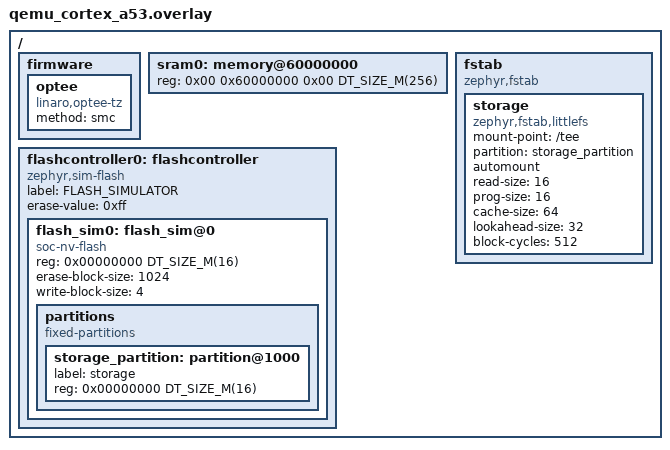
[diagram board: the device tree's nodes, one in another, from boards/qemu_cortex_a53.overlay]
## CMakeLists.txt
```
# SPDX-License-Identifier: GPL-v2
#
# Copyright (c) 2023 EPAM Systems
# Author: Dmytro Semenets <dmytro_semenets@epam.com>

cmake_minimum_required(VERSION 3.20.0)
find_package(Zephyr REQUIRED HINTS $ENV{ZEPHYR_BASE})
include($ENV{ZEPHYR_BASE}/cmake/app/boilerplate.cmake NO_POLICY_SCOPE)
project(zephyr-optee-test)
find_package(Python REQUIRED)

set(EMBED_8100FILE_DIR ${CMAKE_CURRENT_BINARY_DIR}/zephyr/include/generated)
macro(EMBED_8100FILE prefix infile)
	add_custom_command(
		OUTPUT  ${EMBED_8100FILE_DIR}/regression_8100_${prefix}.h
		COMMAND ${Python_EXECUTABLE} ${CMAKE_CURRENT_SOURCE_DIR}/scripts/file_to_c.py --inf ${infile}
			--out ${EMBED_8100FILE_DIR}/regression_8100_${prefix}.h
			--name regression_8100_${prefix}
		DEPENDS ${CMAKE_CURRENT_SOURCE_DIR}/scripts/file_to_c.py ${infile}
	)

	set_property(SOURCE src/regression_8100.c APPEND PROPERTY OBJECT_DEPENDS
		     ${EMBED_8100FILE_DIR}/regression_8100_${prefix}.h)
endmacro(EMBED_8100FILE)

EMBED_8100FILE(ca_crt ${CMAKE_CURRENT_SOURCE_DIR}/cert/ca.crt)
EMBED_8100FILE(mid_crt ${CMAKE_CURRENT_SOURCE_DIR}/cert/mid.crt)
EMBED_8100FILE(my_crt ${CMAKE_CURRENT_SOURCE_DIR}/cert/my.crt)
EMBED_8100FILE(my_csr ${CMAKE_CURRENT_SOURCE_DIR}/cert/my.csr)

zephyr_library_sources(adbg/src/adbg_expect.c)
zephyr_library_sources(adbg/src/adbg_log.c)
zephyr_library_sources(adbg/src/security_utils_hex.c)
zephyr_include_directories(adbg/include)

zephyr_library_include_directories(include)
zephyr_library_sources(src/optee_test.c)
zephyr_library_sources(src/xtest_helpers.c)

zephyr_library_sources(src/regression_1000.c)
zephyr_library_sources(src/pkcs11_1000.c)
zephyr_library_sources(src/regression_4000.c)
zephyr_library_sources(src/regression_4100.c)
zephyr_library_sources(src/regression_6000.c)
zephyr_library_sources(src/regression_8000.c)
zephyr_library_sources(src/regression_8100.c)
# ######################################################################################################################
# External libs
# ######################################################################################################################

zephyr_library_include_directories(${ZEPHYR_OPTEELIB_MODULE_DIR}/public)

# ######################################################################################################################
# Prebuilt TAs
# ######################################################################################################################

if(TA_DEPLOY_DIR)
    message(WARNING "Setting up TAs")
    set(TA_BIN_DIRECTORY ta_bin)
    set(GENERATED_DIRECTORY ta_table)
    add_custom_command(
        OUTPUT
            ${GENERATED_DIRECTORY}/ta_table.c
            ${GENERATED_DIRECTORY}/ta_table.S
        COMMAND ${CMAKE_CURRENT_SOURCE_DIR}/scripts/prepare_ta.sh
                -s ${CMAKE_CURRENT_SOURCE_DIR}
                -f ${TA_DEPLOY_DIR}
                -b ${TA_BIN_DIRECTORY}
                -g ${GENERATED_DIRECTORY}
    )
    include_directories(app PRIVATE ${CMAKE_CURRENT_BINARY_DIR}/${TA_BIN_DIRECTORY})
    zephyr_library_sources(${GENERATED_DIRECTORY}/ta_table.c)
    zephyr_library_sources(${GENERATED_DIRECTORY}/ta_table.S)

endif()
```

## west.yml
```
# SPDX-License-Identifier: Apache-2.0

manifest:
  self:
    path: zephyr-optee-test

  remotes:
    - name: xentroops
      url-base: https://github.com/xen-troops

    - name: zephyr
      url-base: https://github.com/zephyrproject-rtos

  projects:
    - name: zephyr
      remote: xentroops
      revision: zephyr-v4.4.0-xt
      west-commands: scripts/west-commands.yml

    - name: zephyr-optee-client
      remote: xentroops
      revision: master

    - name: littlefs
      remote: zephyr
      path: modules/fs/littlefs
      groups:
        - fs
      revision: ca583fd297ceb48bced3c2548600dc615d67af24
```

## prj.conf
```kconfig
CONFIG_ZTEST=y
CONFIG_OPTEE_CLIENT=y
CONFIG_OPTEE_LIBTEEC=y
CONFIG_OPTEE_LIBCKTEEC=y
CONFIG_HEAP_MEM_POOL_SIZE=8388608
CONFIG_KERNEL_VM_SIZE=0x4000000
CONFIG_TEE=y
CONFIG_OPTEE=y
CONFIG_COMMON_LIBC_MALLOC_ARENA_SIZE=4096
CONFIG_ZTEST_STACK_SIZE=65536

CONFIG_POSIX_TIMERS=y
CONFIG_OPTEE_TEE_SUPPLICANT=y
CONFIG_FILE_SYSTEM=y
CONFIG_FILE_SYSTEM_LITTLEFS=y
CONFIG_POSIX_FILE_SYSTEM=y
CONFIG_POSIX_API=y
CONFIG_DISK_ACCESS=y
CONFIG_DISK_DRIVERS=y

CONFIG_SHELL=y

CONFIG_FLASH=y
CONFIG_FLASH_SHELL=y
CONFIG_FLASH_SIMULATOR=y
CONFIG_FLASH_MAP=y
CONFIG_FLASH_PAGE_LAYOUT=y
CONFIG_FS_LOG_LEVEL_DBG=y
CONFIG_FS_LITTLEFS_BLK_DEV=y
CONFIG_FS_LITTLEFS_NUM_FILES=8
```

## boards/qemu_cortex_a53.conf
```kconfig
CONFIG_ARMV8_A_NS=y
 
```

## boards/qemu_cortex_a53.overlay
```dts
/delete-node/ &sram0;

/ {

	firmware {
		optee {
			compatible = "linaro,optee-tz";
			method = "smc";
			status = "okay";
		};
	};

	sram0: memory@60000000 {
		device_type = "mmio-sram";
		reg = <0x00 0x60000000 0x00 DT_SIZE_M(256)>;
	};

	fstab {
		compatible = "zephyr,fstab";
		storage: storage {
			compatible = "zephyr,fstab,littlefs";
			mount-point = "/tee";
			partition = <&storage_partition>;
			automount;
			read-size = <16>;
			prog-size = <16>;
			cache-size = <64>;
			lookahead-size = <32>;
			block-cycles = <512>;
			status = "okay";
		};
	};

	flashcontroller0: flashcontroller {
		compatible = "zephyr,sim-flash";
		label = "FLASH_SIMULATOR";
		#address-cells = <1>;
		#size-cells = <1>;
		erase-value = <0xff>;
		flash_sim0: flash_sim@0 {
			compatible = "soc-nv-flash";
			reg = <0x00000000 DT_SIZE_M(16)>;
			erase-block-size = <1024>;
			write-block-size = <4>;
			partitions {
				compatible = "fixed-partitions";
				#address-cells = <1>;
				#size-cells = <1>;
				/*
				* Storage partition will be used by FCB/LittleFS/NVS
				* if enabled.
				*/
				storage_partition: partition@1000 {
					label = "storage";
					reg = <0x00000000 DT_SIZE_M(16)>;
				};
			};
		};
	};
};
```

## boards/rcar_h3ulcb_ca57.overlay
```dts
/*
 * Copyright (C) 2023 EPAM Systems, Inc.
 *
 * SPDX-License-Identifier: Apache-2.0
 */

/delete-node/ &ram;

/ {
	firmware {
		optee {
			compatible = "linaro,optee-tz";
			method = "smc";
			status = "okay";
		};
	};

	ram: memory@70000000 {
		device_type = "mmio-sram";
		reg = <0x00 0x70000000 0x00 DT_SIZE_M(256)>;
	};

	fstab {
		compatible = "zephyr,fstab";
		storage: storage {
			compatible = "zephyr,fstab,littlefs";
			mount-point = "/tee";
			partition = <&storage_partition>;
			automount;
			read-size = <16>;
			prog-size = <16>;
			cache-size = <64>;
			lookahead-size = <32>;
			block-cycles = <512>;
			status = "okay";
		};
	};

	flashcontroller0: flashcontroller {
		compatible = "zephyr,sim-flash";
		label = "FLASH_SIMULATOR";
		#address-cells = <1>;
		#size-cells = <1>;
		erase-value = <0xff>;
		flash_sim0: flash_sim@0 {
			compatible = "soc-nv-flash";
			reg = <0x00000000 DT_SIZE_M(16)>;
			erase-block-size = <1024>;
			write-block-size = <4>;
			partitions {
				compatible = "fixed-partitions";
				#address-cells = <1>;
				#size-cells = <1>;
				/*
				* Storage partition will be used by FCB/LittleFS/NVS
				* if enabled.
				*/
				storage_partition: partition@1000 {
					label = "storage";
					reg = <0x00000000 DT_SIZE_M(16)>;
				};
			};
		};
	};
};
```

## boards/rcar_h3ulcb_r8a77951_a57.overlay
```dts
/*
 * Copyright (C) 2023 EPAM Systems, Inc.
 *
 * SPDX-License-Identifier: Apache-2.0
 */

/delete-node/ &ram;

/ {
	firmware {
		optee {
			compatible = "linaro,optee-tz";
			method = "smc";
			status = "okay";
		};
	};

	ram: memory@48000000 {
		device_type = "mmio-sram";
		reg = <0x00 0x48000000 0x00 DT_SIZE_M(256)>;
	};

	fstab {
		compatible = "zephyr,fstab";
		storage: storage {
			compatible = "zephyr,fstab,littlefs";
			mount-point = "/tee";
			partition = <&storage_partition>;
			automount;
			read-size = <16>;
			prog-size = <16>;
			cache-size = <64>;
			lookahead-size = <32>;
			block-cycles = <512>;
			status = "okay";
		};
	};

	flashcontroller0: flashcontroller {
		compatible = "zephyr,sim-flash";
		label = "FLASH_SIMULATOR";
		#address-cells = <1>;
		#size-cells = <1>;
		erase-value = <0xff>;
		flash_sim0: flash_sim@0 {
			compatible = "soc-nv-flash";
			reg = <0x00000000 DT_SIZE_M(16)>;
			erase-block-size = <1024>;
			write-block-size = <4>;
			partitions {
				compatible = "fixed-partitions";
				#address-cells = <1>;
				#size-cells = <1>;
				/*
				* Storage partition will be used by FCB/LittleFS/NVS
				* if enabled.
				*/
				storage_partition: partition@1000 {
					label = "storage";
					reg = <0x00000000 DT_SIZE_M(16)>;
				};
			};
		};
	};
};
```

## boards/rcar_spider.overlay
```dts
/*
 * Copyright (C) 2023 EPAM Systems, Inc.
 *
 * SPDX-License-Identifier: Apache-2.0
 */

/ {
	firmware {
		optee {
			compatible = "linaro,optee-tz";
			method = "smc";
			status = "okay";
		};
	};
};
```

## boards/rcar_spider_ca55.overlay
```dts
/*
 * Copyright (C) 2023 EPAM Systems, Inc.
 *
 * SPDX-License-Identifier: Apache-2.0
 */

/ {
	firmware {
		optee {
			compatible = "linaro,optee-tz";
			method = "smc";
			status = "okay";
		};
	};

	fstab {
		compatible = "zephyr,fstab";
		storage: storage {
			compatible = "zephyr,fstab,littlefs";
			mount-point = "/tee";
			partition = <&storage_partition>;
			automount;
			read-size = <16>;
			prog-size = <16>;
			cache-size = <64>;
			lookahead-size = <32>;
			block-cycles = <512>;
			status = "okay";
		};
	};

	flashcontroller0: flashcontroller {
		compatible = "zephyr,sim-flash";
		label = "FLASH_SIMULATOR";
		#address-cells = <1>;
		#size-cells = <1>;
		erase-value = <0xff>;
		flash_sim0: flash_sim@0 {
			compatible = "soc-nv-flash";
			reg = <0x00000000 DT_SIZE_M(16)>;
			erase-block-size = <1024>;
			write-block-size = <4>;
			partitions {
				compatible = "fixed-partitions";
				#address-cells = <1>;
				#size-cells = <1>;
				/*
				* Storage partition will be used by FCB/LittleFS/NVS
				* if enabled.
				*/
				storage_partition: partition@1000 {
					label = "storage";
					reg = <0x00000000 DT_SIZE_M(16)>;
				};
			};
		};
	};
};
```

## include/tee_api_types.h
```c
/* SPDX-License-Identifier: BSD-2-Clause */
/*
 * Copyright (c) 2014, STMicroelectronics International N.V.
 */

/* Based on GP TEE Internal API Specification Version 0.11 */
#ifndef TEE_API_TYPES_H
#define TEE_API_TYPES_H

#include <inttypes.h>
#include <stdbool.h>
#include <stddef.h>
#include <tee_api_defines.h>

/*
 * Common Definitions
 */

typedef uint32_t TEE_Result;

typedef struct {
	uint32_t timeLow;
	uint16_t timeMid;
	uint16_t timeHiAndVersion;
	uint8_t clockSeqAndNode[8];
} TEE_UUID;

/*
 * The TEE_Identity structure defines the full identity of a Client:
 * - login is one of the TEE_LOGIN_XXX constants
 * - uuid contains the client UUID or Nil if not applicable
 */
typedef struct {
	uint32_t login;
	TEE_UUID uuid;
} TEE_Identity;

/*
 * This union describes one parameter passed by the Trusted Core Framework
 * to the entry points TA_OpenSessionEntryPoint or
 * TA_InvokeCommandEntryPoint or by the TA to the functions
 * TEE_OpenTASession or TEE_InvokeTACommand.
 *
 * Which of the field value or memref to select is determined by the
 * parameter type specified in the argument paramTypes passed to the entry
 * point.
*/
typedef union {
	struct {
		void *buffer;
		uint32_t size;
	} memref;
	struct {
		uint32_t a;
		uint32_t b;
	} value;
} TEE_Param;

/*
 * The type of opaque handles on TA Session. These handles are returned by
 * the function TEE_OpenTASession.
 */
typedef struct __TEE_TASessionHandle *TEE_TASessionHandle;

/*
 * The type of opaque handles on property sets or enumerators. These
 * handles are either one of the pseudo handles TEE_PROPSET_XXX or are
 * returned by the function TEE_AllocatePropertyEnumerator.
*/
typedef struct __TEE_PropSetHandle *TEE_PropSetHandle;

typedef struct __TEE_ObjectHandle *TEE_ObjectHandle;
typedef struct __TEE_ObjectEnumHandle *TEE_ObjectEnumHandle;
typedef struct __TEE_OperationHandle *TEE_OperationHandle;

/*
 * Storage Definitions
 */

typedef uint32_t TEE_ObjectType;

typedef struct {
	uint32_t objectType;
	__extension__ union {
		uint32_t keySize;	/* used in 1.1 spec */
		uint32_t objectSize;	/* used in 1.1.1 spec */
	};
	__extension__ union {
		uint32_t maxKeySize;	/* used in 1.1 spec */
		uint32_t maxObjectSize;	/* used in 1.1.1 spec */
	};
	uint32_t objectUsage;
	uint32_t dataSize;
	uint32_t dataPosition;
	uint32_t handleFlags;
} TEE_ObjectInfo;

typedef enum {
	TEE_DATA_SEEK_SET = 0,
	TEE_DATA_SEEK_CUR = 1,
	TEE_DATA_SEEK_END = 2
} TEE_Whence;

typedef struct {
	uint32_t attributeID;
	union {
		struct {
			void *buffer;
			uint32_t length;
		} ref;
		struct {
			uint32_t a, b;
		} value;
	} content;
} TEE_Attribute;

/* Cryptographic Operations API */

typedef enum {
	TEE_MODE_ENCRYPT = 0,
	TEE_MODE_DECRYPT = 1,
	TEE_MODE_SIGN = 2,
	TEE_MODE_VERIFY = 3,
	TEE_MODE_MAC = 4,
	TEE_MODE_DIGEST = 5,
	TEE_MODE_DERIVE = 6
} TEE_OperationMode;

typedef struct {
	uint32_t algorithm;
	uint32_t operationClass;
	uint32_t mode;
	uint32_t digestLength;
	uint32_t maxKeySize;
	uint32_t keySize;
	uint32_t requiredKeyUsage;
	uint32_t handleState;
} TEE_OperationInfo;

typedef struct {
	uint32_t keySize;
	uint32_t requiredKeyUsage;
} TEE_OperationInfoKey;

typedef struct {
	uint32_t algorithm;
	uint32_t operationClass;
	uint32_t mode;
	uint32_t digestLength;
	uint32_t maxKeySize;
	uint32_t handleState;
	uint32_t operationState;
	uint32_t numberOfKeys;
	TEE_OperationInfoKey keyInformation[];
} TEE_OperationInfoMultiple;

/* Time & Date API */

typedef struct {
	uint32_t seconds;
	uint32_t millis;
} TEE_Time;

/* TEE Arithmetical APIs */

typedef uint32_t TEE_BigInt;

typedef uint32_t TEE_BigIntFMM;

typedef uint32_t TEE_BigIntFMMContext __aligned(__alignof__(void *));

/* Tee Secure Element APIs */

typedef struct __TEE_SEServiceHandle *TEE_SEServiceHandle;
typedef struct __TEE_SEReaderHandle *TEE_SEReaderHandle;
typedef struct __TEE_SESessionHandle *TEE_SESessionHandle;
typedef struct __TEE_SEChannelHandle *TEE_SEChannelHandle;

typedef struct {
	bool sePresent;
	bool teeOnly;
	bool selectResponseEnable;
} TEE_SEReaderProperties;

typedef struct {
	uint8_t *buffer;
	size_t bufferLen;
} TEE_SEAID;

/* Other definitions */
typedef uint32_t TEE_ErrorOrigin;
typedef void *TEE_Session;

#define TEE_MEM_INPUT   0x00000001
#define TEE_MEM_OUTPUT  0x00000002

#define TEE_MEMREF_0_USED  0x00000001
#define TEE_MEMREF_1_USED  0x00000002
#define TEE_MEMREF_2_USED  0x00000004
#define TEE_MEMREF_3_USED  0x00000008

#define TEE_SE_READER_NAME_MAX	20

#endif /* TEE_API_TYPES_H */
```

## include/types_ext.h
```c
/* SPDX-License-Identifier: BSD-2-Clause */
/*
 * Copyright (c) 2014, STMicroelectronics International N.V.
 */
#ifndef __TYPES_EXT_H
#define __TYPES_EXT_H

#include <limits.h>
#include <stddef.h>
#include <inttypes.h>
#include <stdbool.h>

typedef uintptr_t uaddr_t;
#define PRIxUA	PRIxPTR

/* typedef uintptr_t vaddr_t; */
#define PRIxVA	PRIxPTR

#if defined(__ILP32__) && defined(CFG_CORE_LARGE_PHYS_ADDR)
typedef uint64_t paddr_t;
typedef uint64_t paddr_size_t;
#define PRIxPA			PRIx64
#define PRIxPASZ		PRIx64
#define __SIZEOF_PADDR__	8
#else
typedef uintptr_t paddr_t;
typedef uintptr_t paddr_size_t;
#define PRIxPA			PRIxPTR
#define PRIxPASZ		PRIxPTR
#define __SIZEOF_PADDR__	__SIZEOF_POINTER__
#endif

#define PRIxVA_WIDTH	((int)(sizeof(vaddr_t) * 2))
#define PRIxPA_WIDTH	((int)(sizeof(paddr_t) * 2))

#endif /* __TYPES_EXT_H */
```

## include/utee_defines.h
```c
/* SPDX-License-Identifier: BSD-2-Clause */
/*
 * Copyright (c) 2014, STMicroelectronics International N.V.
 * Copyright (c) 2021, SumUp Services GmbH
 */
#ifndef UTEE_DEFINES_H
#define UTEE_DEFINES_H

#include <tee_api_defines.h>
#include <tee_api_defines_extensions.h>
#include <types_ext.h>

/*
 * Copied from TEE Internal API specificaion v1.0 table 6-9 "Structure of
 * Algorithm Identifier".
 */
#define TEE_MAIN_ALGO_MD5        0x01
#define TEE_MAIN_ALGO_SHA1       0x02
#define TEE_MAIN_ALGO_SHA224     0x03
#define TEE_MAIN_ALGO_SHA256     0x04
#define TEE_MAIN_ALGO_SHA384     0x05
#define TEE_MAIN_ALGO_SHA512     0x06
#define TEE_MAIN_ALGO_SM3        0x07
#define TEE_MAIN_ALGO_AES        0x10
#define TEE_MAIN_ALGO_DES        0x11
#define TEE_MAIN_ALGO_DES2       0x12
#define TEE_MAIN_ALGO_DES3       0x13
#define TEE_MAIN_ALGO_SM4        0x14 /* Not in v1.2, extrapolated */
#define TEE_MAIN_ALGO_RSA        0x30
#define TEE_MAIN_ALGO_DSA        0x31
#define TEE_MAIN_ALGO_DH         0x32
#define TEE_MAIN_ALGO_ECDSA      0x41
#define TEE_MAIN_ALGO_ECDH       0x42
#define TEE_MAIN_ALGO_SM2_DSA_SM3 0x45 /* Not in v1.2 spec */
#define TEE_MAIN_ALGO_SM2_KEP    0x46 /* Not in v1.2 spec */
#define TEE_MAIN_ALGO_SM2_PKE    0x47 /* Not in v1.2 spec */
#define TEE_MAIN_ALGO_HKDF       0xC0 /* OP-TEE extension */
#define TEE_MAIN_ALGO_CONCAT_KDF 0xC1 /* OP-TEE extension */
#define TEE_MAIN_ALGO_PBKDF2     0xC2 /* OP-TEE extension */
#define TEE_MAIN_ALGO_X25519     0x44 /* Not in v1.2 spec */


#define TEE_CHAIN_MODE_ECB_NOPAD        0x0
#define TEE_CHAIN_MODE_CBC_NOPAD        0x1
#define TEE_CHAIN_MODE_CTR              0x2
#define TEE_CHAIN_MODE_CTS              0x3
#define TEE_CHAIN_MODE_XTS              0x4
#define TEE_CHAIN_MODE_CBC_MAC_PKCS5    0x5
#define TEE_CHAIN_MODE_CMAC             0x6
#define TEE_CHAIN_MODE_CCM              0x7
#define TEE_CHAIN_MODE_GCM              0x8
#define TEE_CHAIN_MODE_PKCS1_PSS_MGF1   0x9	/* ??? */


static inline uint32_t __tee_alg_get_class(uint32_t algo)
{
	if (algo == TEE_ALG_SM2_PKE)
		return TEE_OPERATION_ASYMMETRIC_CIPHER;
	if (algo == TEE_ALG_SM2_KEP)
		return TEE_OPERATION_KEY_DERIVATION;
	if (algo == TEE_ALG_RSASSA_PKCS1_V1_5)
		return TEE_OPERATION_ASYMMETRIC_SIGNATURE;
	if (algo == TEE_ALG_DES3_CMAC)
		return TEE_OPERATION_MAC;

	return (algo >> 28) & 0xF; /* Bits [31:28] */
}

#define TEE_ALG_GET_CLASS(algo) __tee_alg_get_class(algo)

static inline uint32_t __tee_alg_get_main_alg(uint32_t algo)
{
	switch (algo) {
	case TEE_ALG_SM2_PKE:
		return TEE_MAIN_ALGO_SM2_PKE;
	case TEE_ALG_SM2_KEP:
		return TEE_MAIN_ALGO_SM2_KEP;
	case TEE_ALG_X25519:
		return TEE_MAIN_ALGO_X25519;
	default:
		break;
	}

	return algo & 0xff;
}

#define TEE_ALG_GET_MAIN_ALG(algo) __tee_alg_get_main_alg(algo)

	/* Bits [11:8] */
#define TEE_ALG_GET_CHAIN_MODE(algo)    (((algo) >> 8) & 0xF)

/*
 * Value not defined in the GP spec, and not used as bits 15-12 of any TEE_ALG*
 * value. TEE_ALG_SM2_DSA_SM3 has value 0x6 for bits 15-12 which would yield the
 * SHA512 digest if we were to apply the bit masks that were valid up to the TEE
 * Internal Core API v1.1.
 */
#define __TEE_MAIN_HASH_SM3 0x7

static inline uint32_t __tee_alg_get_digest_hash(uint32_t algo)
{
	if (algo == TEE_ALG_SM2_DSA_SM3)
		return __TEE_MAIN_HASH_SM3;

	/* Bits [15:12] */
	return (algo >> 12) & 0xF;
}

#define TEE_ALG_GET_DIGEST_HASH(algo) __tee_alg_get_digest_hash(algo)

	/* Bits [23:20] */
#define TEE_ALG_GET_INTERNAL_HASH(algo) (((algo) >> 20) & 0x7)

static inline uint32_t __tee_alg_get_key_type(uint32_t algo, bool with_priv)
{
	uint32_t key_type = 0xA0000000 |  TEE_ALG_GET_MAIN_ALG(algo);

	if (with_priv)
		key_type |= 0x01000000;

	return key_type;
}

#define TEE_ALG_GET_KEY_TYPE(algo, with_private_key) \
	__tee_alg_get_key_type(algo, with_private_key)

static inline uint32_t __tee_alg_hash_algo(uint32_t main_hash)
{
	if (main_hash == __TEE_MAIN_HASH_SM3)
		return TEE_ALG_SM3;

	return (TEE_OPERATION_DIGEST << 28) | main_hash;
}

	/* Return hash algorithm based on main hash */
#define TEE_ALG_HASH_ALGO(main_hash) __tee_alg_hash_algo(main_hash)

	/* Extract internal hash and return hash algorithm */
#define TEE_INTERNAL_HASH_TO_ALGO(algo) \
                TEE_ALG_HASH_ALGO(TEE_ALG_GET_INTERNAL_HASH(algo))

	/* Extract digest hash and return hash algorithm */
#define TEE_DIGEST_HASH_TO_ALGO(algo) \
                TEE_ALG_HASH_ALGO(TEE_ALG_GET_DIGEST_HASH(algo))

/* Return HMAC algorithm based on main hash */
#define TEE_ALG_HMAC_ALGO(main_hash) \
	(TEE_OPERATION_MAC << 28 | (main_hash))

#define TEE_AES_BLOCK_SIZE  16UL
#define TEE_DES_BLOCK_SIZE  8UL
#define TEE_SM4_BLOCK_SIZE  16UL

#define TEE_AES_MAX_KEY_SIZE    32UL

	/* SHA-512 */
#ifndef TEE_MD5_HASH_SIZE
typedef enum {
	TEE_MD5_HASH_SIZE = 16,
	TEE_SHA1_HASH_SIZE = 20,
	TEE_SHA224_HASH_SIZE = 28,
	TEE_SHA256_HASH_SIZE = 32,
	TEE_SM3_HASH_SIZE = 32,
	TEE_SHA384_HASH_SIZE = 48,
	TEE_SHA512_HASH_SIZE = 64,
	TEE_MD5SHA1_HASH_SIZE = (TEE_MD5_HASH_SIZE + TEE_SHA1_HASH_SIZE),
	TEE_MAX_HASH_SIZE = 64,
} t_hash_size;
#endif

#define TEE_MAC_SIZE_AES_CBC_MAC_NOPAD
#define TEE_MAC_SIZE_AES_CBC_MAC_PKCS5
#define TEE_MAC_SIZE_AES_CMAC
#define TEE_MAC_SIZE_DES_CBC_MAC_PKCS5

static inline size_t __tee_alg_get_digest_size(uint32_t algo)
{
	switch (algo) {
	case TEE_ALG_MD5:
	case TEE_ALG_HMAC_MD5:
		return TEE_MD5_HASH_SIZE;
	case TEE_ALG_SHA1:
	case TEE_ALG_HMAC_SHA1:
	case TEE_ALG_DSA_SHA1:
		return TEE_SHA1_HASH_SIZE;
	case TEE_ALG_SHA224:
	case TEE_ALG_HMAC_SHA224:
	case TEE_ALG_DSA_SHA224:
		return TEE_SHA224_HASH_SIZE;
	case TEE_ALG_SHA256:
	case TEE_ALG_HMAC_SHA256:
	case TEE_ALG_DSA_SHA256:
		return TEE_SHA256_HASH_SIZE;
	case TEE_ALG_SHA384:
	case TEE_ALG_HMAC_SHA384:
		return TEE_SHA384_HASH_SIZE;
	case TEE_ALG_SHA512:
	case TEE_ALG_HMAC_SHA512:
		return TEE_SHA512_HASH_SIZE;
	case TEE_ALG_SM3:
	case TEE_ALG_HMAC_SM3:
		return TEE_SM3_HASH_SIZE;
	case TEE_ALG_AES_CBC_MAC_NOPAD:
	case TEE_ALG_AES_CBC_MAC_PKCS5:
	case TEE_ALG_AES_CMAC:
		return TEE_AES_BLOCK_SIZE;
	case TEE_ALG_DES_CBC_MAC_NOPAD:
	case TEE_ALG_DES_CBC_MAC_PKCS5:
	case TEE_ALG_DES3_CBC_MAC_NOPAD:
	case TEE_ALG_DES3_CBC_MAC_PKCS5:
	case TEE_ALG_DES3_CMAC:
		return TEE_DES_BLOCK_SIZE;
	default:
		return 0;
	}
}

	/* Return algorithm digest size */
#define TEE_ALG_GET_DIGEST_SIZE(algo) __tee_alg_get_digest_size(algo)

/*
 * Bit indicating that the attribute is a value attribute
 * See TEE Internal API specificaion v1.0 table 6-12 "Partial Structure of
 * Attribute Identifier"
 */


#ifdef __compiler_bswap64
#define TEE_U64_BSWAP(x) __compiler_bswap64((x))
#else
#define TEE_U64_BSWAP(x) ((uint64_t)( \
        (((uint64_t)(x) & UINT64_C(0xff00000000000000ULL)) >> 56) | \
        (((uint64_t)(x) & UINT64_C(0x00ff000000000000ULL)) >> 40) | \
        (((uint64_t)(x) & UINT64_C(0x0000ff0000000000ULL)) >> 24) | \
        (((uint64_t)(x) & UINT64_C(0x000000ff00000000ULL)) >>  8) | \
        (((uint64_t)(x) & UINT64_C(0x00000000ff000000ULL)) <<  8) | \
        (((uint64_t)(x) & UINT64_C(0x0000000000ff0000ULL)) << 24) | \
        (((uint64_t)(x) & UINT64_C(0x000000000000ff00ULL)) << 40) | \
        (((uint64_t)(x) & UINT64_C(0x00000000000000ffULL)) << 56)))
#endif

#ifdef __compiler_bswap32
#define TEE_U32_BSWAP(x) __compiler_bswap32((x))
#else
#define TEE_U32_BSWAP(x) ((uint32_t)( \
        (((uint32_t)(x) & UINT32_C(0xff000000)) >> 24) | \
        (((uint32_t)(x) & UINT32_C(0x00ff0000)) >>  8) | \
        (((uint32_t)(x) & UINT32_C(0x0000ff00)) <<  8) | \
        (((uint32_t)(x) & UINT32_C(0x000000ff)) << 24)))
#endif

#ifdef __compiler_bswap16
#define TEE_U16_BSWAP(x) __compiler_bswap16((x))
#else
#define TEE_U16_BSWAP(x) ((uint16_t)( \
        (((uint16_t)(x) & UINT16_C(0xff00)) >> 8) | \
        (((uint16_t)(x) & UINT16_C(0x00ff)) << 8)))
#endif

/* If we we're on a big endian platform we'll have to update these */
#define TEE_U64_FROM_BIG_ENDIAN(x)  TEE_U64_BSWAP(x)
#define TEE_U32_FROM_BIG_ENDIAN(x)  TEE_U32_BSWAP(x)
#define TEE_U16_FROM_BIG_ENDIAN(x)  TEE_U16_BSWAP(x)
#define TEE_U64_TO_BIG_ENDIAN(x)    TEE_U64_BSWAP(x)
#define TEE_U32_TO_BIG_ENDIAN(x)    TEE_U32_BSWAP(x)
#define TEE_U16_TO_BIG_ENDIAN(x)    TEE_U16_BSWAP(x)

#define TEE_TIME_MILLIS_BASE    1000

#define TEE_TIME_LT(t1, t2)				\
    (((t1).seconds == (t2).seconds) ?			\
        ((t1).millis < (t2).millis) :			\
        ((t1).seconds < (t2).seconds))

#define TEE_TIME_LE(t1, t2)				\
    (((t1).seconds == (t2).seconds) ?			\
        ((t1).millis <= (t2).millis) :			\
        ((t1).seconds <= (t2).seconds))

#define TEE_TIME_ADD(t1, t2, dst) do {                      \
        (dst).seconds = (t1).seconds + (t2).seconds;        \
        (dst).millis = (t1).millis + (t2).millis;           \
        if ((dst).millis >= TEE_TIME_MILLIS_BASE) {         \
            (dst).seconds++;                                \
            (dst).millis -= TEE_TIME_MILLIS_BASE;           \
        }                                                   \
    } while (0)

#define TEE_TIME_SUB(t1, t2, dst) do {                      \
        (dst).seconds = (t1).seconds - (t2).seconds;        \
        if ((t1).millis < (t2).millis) {                    \
            (dst).seconds--;                                \
            (dst).millis = (t1).millis + TEE_TIME_MILLIS_BASE - (t2).millis;\
        } else {                                            \
            (dst).millis = (t1).millis - (t2).millis;       \
        }                                                   \
    } while (0)

/* ------------------------------------------------------------ */
/* OTP mapping                                                  */
/* ------------------------------------------------------------ */
#define HW_UNIQUE_KEY_WORD1      (8)
#define HW_UNIQUE_KEY_LENGTH     (16)
#define HW_UNIQUE_KEY_WORD2      (HW_UNIQUE_KEY_WORD1 + 1)
#define HW_UNIQUE_KEY_WORD3      (HW_UNIQUE_KEY_WORD1 + 2)
#define HW_UNIQUE_KEY_WORD4      (HW_UNIQUE_KEY_WORD1 + 3)

#define UTEE_SE_READER_PRESENT			(1 << 0)
#define UTEE_SE_READER_TEE_ONLY			(1 << 1)
#define UTEE_SE_READER_SELECT_RESPONE_ENABLE	(1 << 2)

#endif /* UTEE_DEFINES_H */
```

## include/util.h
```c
/* SPDX-License-Identifier: BSD-2-Clause */
/*
 * Copyright (c) 2014, STMicroelectronics International N.V.
 */
#ifndef UTIL_H
#define UTIL_H

#include <inttypes.h>

#define SIZE_4K	UINTPTR_C(0x1000)
#define SIZE_1M	UINTPTR_C(0x100000)
#define SIZE_2M	UINTPTR_C(0x200000)
#define SIZE_4M	UINTPTR_C(0x400000)
#define SIZE_8M	UINTPTR_C(0x800000)
#define SIZE_2G	UINTPTR_C(0x80000000)

#ifndef MAX
#ifndef __ASSEMBLER__
#define MAX(a, b) \
	(__extension__({ __typeof__(a) _a = (a); \
	   __typeof__(b) _b = (b); \
	 _a > _b ? _a : _b; }))

#define MIN(a, b) \
	(__extension__({ __typeof__(a) _a = (a); \
	   __typeof__(b) _b = (b); \
	 _a < _b ? _a : _b; }))
#else
#define MAX(a, b)	(((a) > (b)) ? (a) : (b))
#define MIN(a, b)	(((a) < (b)) ? (a) : (b))
#endif
#endif

/*
 * In some particular conditions MAX and MIN macros fail to
 * build from C source file implmentation. In such case one
 * need to use MAX_UNSAFE/MIN_UNSAFE instead.
 */
#define MAX_UNSAFE(a, b)	(((a) > (b)) ? (a) : (b))
#define MIN_UNSAFE(a, b)	(((a) < (b)) ? (a) : (b))

#ifndef __ASSEMBLER__
/* Round up the even multiple of size, size has to be a multiple of 2 */
#define ROUNDUP(v, size) (((v) + ((__typeof__(v))(size) - 1)) & \
			  ~((__typeof__(v))(size) - 1))

#define ROUNDUP_OVERFLOW(v, size, res) (__extension__({ \
	typeof(*(res)) __roundup_tmp = 0; \
	typeof(v) __roundup_mask = (typeof(v))(size) - 1; \
	\
	ADD_OVERFLOW((v), __roundup_mask, &__roundup_tmp) ? 1 : \
		((void)(*(res) = __roundup_tmp & ~__roundup_mask), 0); \
}))

/*
 * Rounds up to the nearest multiple of y and then divides by y. Safe
 * against overflow, y has to be a multiple of 2.
 *
 * This macro is intended to be used to convert from "number of bytes" to
 * "number of pages" or similar units. Example:
 * num_pages = ROUNDUP_DIV(num_bytes, SMALL_PAGE_SIZE);
 */
#define ROUNDUP_DIV(x, y) (__extension__({ \
	typeof(x) __roundup_x = (x); \
	typeof(y) __roundup_mask = (typeof(x))(y) - 1; \
	\
	(__roundup_x / (y)) + (__roundup_x & __roundup_mask ? 1 : 0); \
}))

/* Round down the even multiple of size, size has to be a multiple of 2 */
#define ROUNDDOWN(v, size) ((v) & ~((__typeof__(v))(size) - 1))

/*
 * Round up the result of x / y to the nearest upper integer if result is not 
 * already an integer.
 */
#define DIV_ROUND_UP(x, y) (((x) + (y) - 1) / (y))

/* Unsigned integer division with nearest rounding variant */
#define UDIV_ROUND_NEAREST(x, y) \
	(__extension__ ({ __typeof__(x) _x = (x); \
	  __typeof__(y) _y = (y); \
	  (_x + (_y / 2)) / _y; }))
#else
#define ROUNDUP(x, y)			((((x) + (y) - 1) / (y)) * (y))
#define ROUNDDOWN(x, y)		(((x) / (y)) * (y))
#define UDIV_ROUND_NEAREST(x, y)	(((x) + ((y) / 2)) / (y))
#endif

/* x has to be of an unsigned type */
#define IS_POWER_OF_TWO(x) (((x) != 0) && (((x) & (~(x) + 1)) == (x)))

#define IS_ALIGNED(x, a)		(((x) & ((a) - 1)) == 0)
#define IS_ALIGNED_WITH_TYPE(x, type) \
        (__extension__({ \
                type __is_aligned_y; \
                IS_ALIGNED((uintptr_t)(x), __alignof__(__is_aligned_y)); \
        }))

#define TO_STR(x) _TO_STR(x)
#define _TO_STR(x) #x

#define CONCAT(x, y) _CONCAT(x, y)

#define container_of(ptr, type, member) \
	(__extension__({ \
		const typeof(((type *)0)->member) *__ptr = (ptr); \
		(type *)((unsigned long)(__ptr) - offsetof(type, member)); \
	}))

#define MEMBER_SIZE(type, member) sizeof(((type *)0)->member)

#ifdef __ASSEMBLER__
#define BIT32(nr)		(1 << (nr))
#define SHIFT_U32(v, shift)	((v) << (shift))
#define SHIFT_U64(v, shift)	((v) << (shift))
#else
#define BIT32(nr)		(UINT32_C(1) << (nr))
#define SHIFT_U32(v, shift)	((uint32_t)(v) << (shift))
#define SHIFT_U64(v, shift)	((uint64_t)(v) << (shift))
#endif

/*
 * Create a contiguous bitmask starting at bit position @l and ending at
 * position @h. For example
 * GENMASK_64(39, 21) gives us the 64bit vector 0x000000ffffe00000.
 */
#define GENMASK_32(h, l) \
	(((~UINT32_C(0)) << (l)) & (~UINT32_C(0) >> (32 - 1 - (h))))

#define GENMASK_64(h, l) \
	(((~UINT64_C(0)) << (l)) & (~UINT64_C(0) >> (64 - 1 - (h))))

/*
 * Checking overflow for addition, subtraction and multiplication. Result
 * of operation is stored in res which is a pointer to some kind of
 * integer.
 *
 * The macros return true if an overflow occurred and *res is undefined.
 */
#define ADD_OVERFLOW(a, b, res) __compiler_add_overflow((a), (b), (res))
#define SUB_OVERFLOW(a, b, res) __compiler_sub_overflow((a), (b), (res))
#define MUL_OVERFLOW(a, b, res) __compiler_mul_overflow((a), (b), (res))

/* Return a signed +1, 0 or -1 value based on data comparison */
#define CMP_TRILEAN(a, b) \
	(__extension__({ \
		__typeof__(a) _a = (a); \
		__typeof__(b) _b = (b); \
		\
		_a > _b ? 1 : _a < _b ? -1 : 0; \
	}))

#ifndef __ASSEMBLER__
static inline uint64_t reg_pair_to_64(uint32_t reg0, uint32_t reg1)
{
	return (uint64_t)reg0 << 32 | reg1;
}

static inline void reg_pair_from_64(uint64_t val, uint32_t *reg0,
				    uint32_t *reg1)
{
	*reg0 = val >> 32;
	*reg1 = val;
}

/* Get and set bit fields  */
static inline uint32_t get_field_u32(uint32_t reg, uint32_t mask)
{
	return (reg & mask) / (mask & ~(mask - 1));
}

static inline uint32_t set_field_u32(uint32_t reg, uint32_t mask, uint32_t val)
{
	return (reg & ~mask) | (val * (mask & ~(mask - 1)));
}

static inline uint64_t get_field_u64(uint64_t reg, uint64_t mask)
{
	return (reg & mask) / (mask & ~(mask - 1));
}

static inline uint64_t set_field_u64(uint64_t reg, uint64_t mask, uint64_t val)
{
	return (reg & ~mask) | (val * (mask & ~(mask - 1)));
}
#endif

#endif /*UTIL_H*/
```

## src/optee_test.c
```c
// SPDX-License-Identifier: GPL-2.0
/*
 * Copyright (c) 2014, STMicroelectronics International N.V.
 * Copyright (c) 2023, EPAM Systems
*/

#include <stdlib.h>
#include <stdint.h>
#include <stdarg.h>
#include <zephyr/kernel.h>
#include <zephyr/ztest.h>
#include <tee_client_api.h>
#include "optee_test.h"

const TEEC_UUID crypt_user_ta_uuid = TA_CRYPT_UUID;
const TEEC_UUID os_test_ta_uuid = TA_OS_TEST_UUID;
const TEEC_UUID create_fail_test_ta_uuid = TA_CREATE_FAIL_TEST_UUID;
const TEEC_UUID ecc_test_ta_uuid = ECC_SELF_TEST_UUID;
const TEEC_UUID pta_invoke_tests_ta_uuid = PTA_INVOKE_TESTS_UUID;
const TEEC_UUID rpc_test_ta_uuid = TA_RPC_TEST_UUID;
const TEEC_UUID sims_test_ta_uuid = TA_SIMS_TEST_UUID;
const TEEC_UUID miss_test_ta_uuid = TA_MISS_TEST_UUID;
const TEEC_UUID sims_keepalive_test_ta_uuid = TA_SIMS_KEEP_ALIVE_TEST_UUID;
const TEEC_UUID storage_ta_uuid = TA_STORAGE_UUID;
const TEEC_UUID storage2_ta_uuid = TA_STORAGE2_UUID;
const TEEC_UUID enc_fs_key_manager_test_ta_uuid = ENC_FS_KEY_MANAGER_TEST_UUID;
const TEEC_UUID concurrent_ta_uuid = TA_CONCURRENT_UUID;
const TEEC_UUID concurrent_large_ta_uuid = TA_CONCURRENT_LARGE_UUID;
const TEEC_UUID storage_benchmark_ta_uuid = TA_STORAGE_BENCHMARK_UUID;
const TEEC_UUID socket_ta_uuid = TA_SOCKET_UUID;
const TEEC_UUID sdp_basic_ta_uuid = TA_SDP_BASIC_UUID;
const TEEC_UUID tpm_log_test_ta_uuid = TA_TPM_LOG_TEST_UUID;
const TEEC_UUID supp_plugin_test_ta_uuid = TA_SUPP_PLUGIN_UUID;
const TEEC_UUID large_ta_uuid = TA_LARGE_UUID;
const TEEC_UUID bti_test_ta_uuid = TA_BTI_UUID;
const TEEC_UUID subkey1_ta_uuid = TA_SUBKEY1_UUID;
const TEEC_UUID subkey2_ta_uuid = TA_SUBKEY2_UUID;

TEEC_Context xtest_teec_ctx;

unsigned int level = 0;
char *xtest_tee_name = NULL;

void BeginTest(const char *msg)
{
	printk("Begin Test -- %s\n", msg);
}

void EndTest(const char *msg)
{
	printk("End Test -- %s\n", msg);
}

void BeginSubCase(const char *format, ...)
{
	va_list ArgList;
	char Title[80] = { };

	if (format == NULL) {
		strcpy(Title, "NULL");
	} else {
		va_start(ArgList, format);
		vsnprintf(Title, sizeof(Title), format, ArgList);
		va_end(ArgList);
	}
	printk("Begin subcase -- %s\n", Title);
}

void EndSubCase(const char *format, ...)
{
	va_list ArgList;
	char Title[80] = { };

	if (format == NULL) {
		strcpy(Title, "NULL");
	} else {
		va_start(ArgList, format);
		vsnprintf(Title, sizeof(Title), format, ArgList);
		va_end(ArgList);
	}
	printk("End subcase -- %s\n", Title);
}


TEEC_Result xtest_teec_ctx_init(void)
{
	return TEEC_InitializeContext(xtest_tee_name, &xtest_teec_ctx);
}

TEEC_Result xtest_teec_open_session(TEEC_Session *session,
				    const TEEC_UUID *uuid, TEEC_Operation *op,
				    uint32_t *ret_orig)
{
	return TEEC_OpenSession(&xtest_teec_ctx, session, uuid,
				TEEC_LOGIN_PUBLIC, NULL, op, ret_orig);
}

void xtest_teec_ctx_deinit(void)
{
	TEEC_FinalizeContext(&xtest_teec_ctx);
}

void xtest_mutex_init(struct k_mutex *mutex)
{
	int e = k_mutex_init(mutex);

	if (e)
		printk( "pthread_mutex_init: %s\n", strerror(e));
}

void xtest_mutex_destroy(struct k_mutex *mutex)
{
	(void)mutex;
}

void xtest_mutex_lock(struct k_mutex *mutex)
{
	int e = k_mutex_lock(mutex, K_FOREVER);

	if (e)
		printk( "pthread_mutex_lock: %s\n", strerror(e));
}

void xtest_mutex_unlock(struct k_mutex *mutex)
{
	int e = k_mutex_unlock(mutex);

	if (e)
		printk( "pthread_mutex_unlock: %s\n", strerror(e));
}
```

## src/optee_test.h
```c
// SPDX-License-Identifier: GPL-2.0
/*
 * Copyright (c) 2014, STMicroelectronics International N.V.
 * Copyright (c) 2023, EPAM Systems
 */

#ifndef __OPTEE_TEST_H
#define __OPTEE_TEST_H

#include <tee_client_api.h>
#include <zephyr/kernel.h>
#include <zephyr/ztest.h>

/* UUIDs */
#include <enc_fs_key_manager_test.h>
#include <pta_invoke_tests.h>
#include <ta_arm_bti.h>
#include <ta_concurrent.h>
#include <ta_concurrent_large.h>
#include <ta_create_fail_test.h>
#include <ta_crypt.h>
#include <ta_large.h>
#include <ta_miss_test.h>
#include <ta_os_test.h>
#include <ta_rpc_test.h>
#include <ta_sdp_basic.h>
#include <ta_sims_keepalive_test.h>
#include <ta_sims_test.h>
#include <ta_socket.h>
#include <ta_storage_benchmark.h>
#include <ta_storage.h>
#include <ta_subkey1.h>
#include <ta_subkey2.h>
#include <ta_supp_plugin.h>
#include <ta_tpm_log_test.h>

#define ECC_SELF_TEST_UUID \
		{ 0xf34f4f3c, 0xab30, 0x4573,  \
		{ 0x91, 0xBF, 0x3C, 0x57, 0x02, 0x4D, 0x51, 0x99 } }

#define TEEC_OPERATION_INITIALIZER	{ }

extern const TEEC_UUID crypt_user_ta_uuid;
extern const TEEC_UUID os_test_ta_uuid;
extern const TEEC_UUID create_fail_test_ta_uuid;
extern const TEEC_UUID ecc_test_ta_uuid;
extern const TEEC_UUID pta_invoke_tests_ta_uuid;
extern const TEEC_UUID rpc_test_ta_uuid;
extern const TEEC_UUID sims_test_ta_uuid;
extern const TEEC_UUID miss_test_ta_uuid;
extern const TEEC_UUID sims_keepalive_test_ta_uuid;
extern const TEEC_UUID storage_ta_uuid;
extern const TEEC_UUID storage2_ta_uuid;
extern const TEEC_UUID enc_fs_key_manager_test_ta_uuid;
extern const TEEC_UUID concurrent_ta_uuid;
extern const TEEC_UUID concurrent_large_ta_uuid;
extern const TEEC_UUID storage_benchmark_ta_uuid;
extern const TEEC_UUID socket_ta_uuid;
extern const TEEC_UUID sdp_basic_ta_uuid;
extern const TEEC_UUID tpm_log_test_ta_uuid;
extern const TEEC_UUID supp_plugin_test_ta_uuid;
extern const TEEC_UUID large_ta_uuid;
extern const TEEC_UUID bti_test_ta_uuid;
extern const TEEC_UUID subkey1_ta_uuid;
extern const TEEC_UUID subkey2_ta_uuid;

void BeginTest(const char *msg);
void EndTest(const char *msg);
void BeginSubCase(const char *msg);
void EndSubCase(const char *msg);

TEEC_Result xtest_teec_ctx_init(void);
TEEC_Result xtest_teec_open_session(TEEC_Session *session,
				    const TEEC_UUID *uuid, TEEC_Operation *op,
				    uint32_t *ret_orig);
void xtest_teec_ctx_deinit(void);
void xtest_mutex_init(struct k_mutex *mutex);
void xtest_mutex_destroy(struct k_mutex *mutex);
void xtest_mutex_lock(struct k_mutex *mutex);
void xtest_mutex_unlock(struct k_mutex *mutex);

#endif      /* __OPTEE_TEST_H */
```
